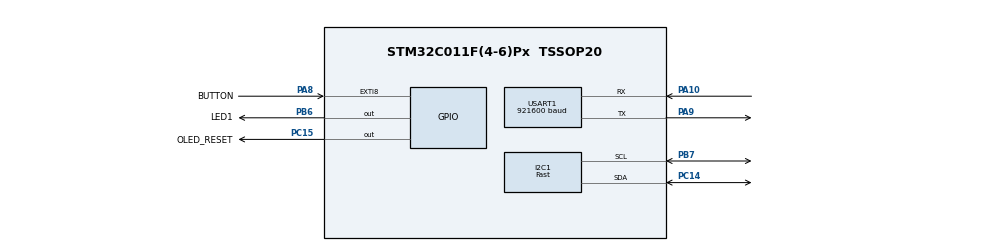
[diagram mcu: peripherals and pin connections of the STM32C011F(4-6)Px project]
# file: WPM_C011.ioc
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ADC1.Channel-0\#ChannelRegularConversion=ADC_CHANNEL_VREFINT
ADC1.Channel-1\#ChannelRegularConversion=ADC_CHANNEL_TEMPSENSOR
ADC1.DMAContinuousRequests=ENABLE
ADC1.ExternalTrigConv=ADC_EXTERNALTRIG_T3_TRGO
ADC1.NbrOfConversion=2
ADC1.NbrOfConversionFlag=1
ADC1.Rank-0\#ChannelRegularConversion=1
ADC1.Rank-1\#ChannelRegularConversion=2
ADC1.SamplingTime-0\#ChannelRegularConversion=ADC_SAMPLINGTIME_COMMON_1
ADC1.SamplingTime-1\#ChannelRegularConversion=ADC_SAMPLINGTIME_COMMON_1
ADC1.SamplingTimeCommon1=ADC_SAMPLETIME_160CYCLES_5
ADC1.SelectedChannel=ADC_CHANNEL_TEMPSENSOR|ADC_CHANNEL_VREFINT
ADC1.master=1
Dma.ADC1.0.Direction=DMA_PERIPH_TO_MEMORY
Dma.ADC1.0.EventEnable=DISABLE
Dma.ADC1.0.Instance=DMA1_Channel1
Dma.ADC1.0.MemDataAlignment=DMA_MDATAALIGN_HALFWORD
Dma.ADC1.0.MemInc=DMA_MINC_ENABLE
Dma.ADC1.0.Mode=DMA_CIRCULAR
Dma.ADC1.0.PeriphDataAlignment=DMA_PDATAALIGN_HALFWORD
Dma.ADC1.0.PeriphInc=DMA_PINC_DISABLE
Dma.ADC1.0.Polarity=HAL_DMAMUX_REQ_GEN_RISING
Dma.ADC1.0.Priority=DMA_PRIORITY_LOW
Dma.ADC1.0.RequestNumber=1
Dma.ADC1.0.SignalID=NONE
Dma.ADC1.0.SyncEnable=DISABLE
Dma.ADC1.0.SyncPolarity=HAL_DMAMUX_SYNC_NO_EVENT
Dma.ADC1.0.SyncRequestNumber=1
Dma.ADC1.0.SyncSignalID=NONE
Dma.Request0=ADC1
I2C1.I2C_Speed_Mode=I2C_Fast
I2C1.Timing=0x2010091A
Mcu.Family=STM32C0
Mcu.Name=STM32C011F(4-6)Px
Mcu.Package=TSSOP20
NVIC.DMA1_Channel1_IRQn=true\:0\:0\:false\:false\:true\:false\:true\:true
NVIC.TIM3_IRQn=true\:0\:0\:false\:false\:true\:true\:true\:true
PA10\ [PA12].Mode=Asynchronous
PA10\ [PA12].Signal=USART1_RX
PA13.Mode=Serial_Wire
PA13.Signal=DEBUG_SWDIO
PA14-BOOT0.Mode=Serial_Wire
PA14-BOOT0.Signal=DEBUG_SWCLK
PA8.GPIO_Label=BUTTON
PA8.Signal=GPXTI8
PA9\ [PA11].Mode=Asynchronous
PA9\ [PA11].Signal=USART1_TX
PB6.GPIO_Label=LED1
PB6.Signal=GPIO_Output
PB7.Mode=I2C
PB7.Signal=I2C1_SCL
PC14-OSCX_IN\ (PC14).Mode=I2C
PC14-OSCX_IN\ (PC14).Signal=I2C1_SDA
PC15-OSCX_OUT\ (PC15).GPIO_Label=OLED_RESET
PC15-OSCX_OUT\ (PC15).Signal=GPIO_Output
ProjectManager.HeapSize=0x200
ProjectManager.StackSize=0x400
ProjectManager.TargetToolchain=STM32CubeIDE
RCC.ADCFreq_Value=48000000
RCC.AHBFreq_Value=48000000
RCC.CortexFreq_Value=48000000
RCC.EXTERNAL_CLOCK_VALUE=12288000
RCC.HCLKFreq_Value=48000000
RCC.HSE_VALUE=8000000
RCC.HSISYSCLKDivider=RCC_HSI_DIV1
RCC.HSI_VALUE=48000000
RCC.LSE_VALUE=32768
RCC.SYSCLKFreq_VALUE=48000000
TIM3.Period=(10 - 1)
TIM3.Prescaler=(48000 - 1)
TIM3.TIM_MasterOutputTrigger=TIM_TRGO_UPDATE
TIM3.TIM_MasterSlaveMode=TIM_MASTERSLAVEMODE_ENABLE
USART1.BaudRate=921600
USART1.VirtualMode-Asynchronous=VM_ASYNC
VP_ADC1_TempSens_Input.Mode=IN-TempSens
VP_ADC1_Vref_Input.Mode=IN-Vrefint
VP_SYS_VS_PINREMAP.Mode=PINREMAP
VP_SYS_VS_PINREMAP_10_12.Mode=PINREMAP_10_12
VP_TIM3_VS_ClockSourceINT.Mode=Internal
board=custom

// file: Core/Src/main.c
/* USER CODE BEGIN Header */
/**
  ******************************************************************************
  * @file           : main.c
  * @brief          : Main program body
  ******************************************************************************
  * @attention
  *
  * Copyright (c) 2023 STMicroelectronics.
  * All rights reserved.
  *
  * This software is licensed under terms that can be found in the LICENSE file
  * in the root directory of this software component.
  * If no LICENSE file comes with this software, it is provided AS-IS.
  *
  ******************************************************************************
  */
/* USER CODE END Header */
#include "main.h"
#include "adc.h"
#include "dma.h"
#include "i2c.h"
#include "tim.h"
#include "usart.h"
#include "gpio.h"

/* USER CODE BEGIN Includes */

#include "app.h"

/* USER CODE END Includes */

void SystemClock_Config(void);

int main(void)
{

  /* MCU Configuration--------------------------------------------------------*/

  /* Reset of all peripherals, Initializes the Flash interface and the Systick. */
  HAL_Init();

  /* Configure the system clock */
  SystemClock_Config();

  /* Initialize all configured peripherals */
  MX_GPIO_Init();
  MX_DMA_Init();
  MX_USART1_UART_Init();
  MX_ADC1_Init();
  MX_I2C1_Init();
  MX_TIM3_Init();
  /* USER CODE BEGIN 2 */

  APP_Run();	// Application code runs from here

  /* USER CODE END 2 */

  /* Infinite loop */
  while (1)
  {

  }
}

void SystemClock_Config(void)
{
  RCC_OscInitTypeDef RCC_OscInitStruct = {0};
  RCC_ClkInitTypeDef RCC_ClkInitStruct = {0};

  /** Initializes the RCC Oscillators according to the specified parameters
  * in the RCC_OscInitTypeDef structure.
  */
  RCC_OscInitStruct.OscillatorType = RCC_OSCILLATORTYPE_HSI;
  RCC_OscInitStruct.HSIState = RCC_HSI_ON;
  RCC_OscInitStruct.HSIDiv = RCC_HSI_DIV1;
  RCC_OscInitStruct.HSICalibrationValue = RCC_HSICALIBRATION_DEFAULT;
  if (HAL_RCC_OscConfig(&RCC_OscInitStruct) != HAL_OK)
  {
    Error_Handler();
  }

  /** Initializes the CPU, AHB and APB buses clocks
  */
  RCC_ClkInitStruct.ClockType = RCC_CLOCKTYPE_HCLK|RCC_CLOCKTYPE_SYSCLK
                              |RCC_CLOCKTYPE_PCLK1;
  RCC_ClkInitStruct.SYSCLKSource = RCC_SYSCLKSOURCE_HSI;
  RCC_ClkInitStruct.SYSCLKDivider = RCC_SYSCLK_DIV1;
  RCC_ClkInitStruct.AHBCLKDivider = RCC_HCLK_DIV1;
  RCC_ClkInitStruct.APB1CLKDivider = RCC_APB1_DIV1;

  if (HAL_RCC_ClockConfig(&RCC_ClkInitStruct, FLASH_LATENCY_1) != HAL_OK)
  {
    Error_Handler();
  }
}

void Error_Handler(void)
{
  __disable_irq();
  while (1)
  {
  }
}
